# STM8S207C6 register map
Vendor: STMicroelectronics; Series: STM8S/STM8AF, medium density; File version: 1.0
CPU: other r1p0, big endian, no MPU, no FPU, 4 interrupt priority bits
Registers are 8-bit, read-write, reset 0x0 unless marked. A register's access mark holds for its fields unless they carry their own. Offsets are from the block's base; [hi:lo] are bit positions; {n}, {i} and the like mark numbered series.

## PORTI
Base 0x00005028
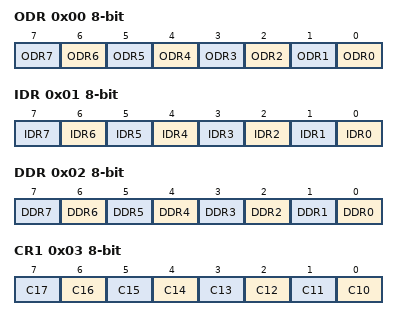
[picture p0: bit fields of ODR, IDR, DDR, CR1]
0x00 ODR — Port I data output latch register
  [n] ODR{n} (n=0..7)
0x01 IDR — Port I input pin value register
  [n] IDR{n} (n=0..7)
0x02 DDR — Port I data direction register
  [n] DDR{n} (n=0..7)
0x03 CR1 — Port I control register 1
  [n-10] C{n} (n=10..17)
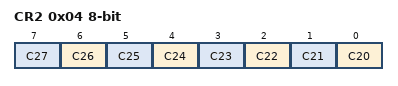
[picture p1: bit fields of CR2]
0x04 CR2 — Port I control register 2
  [n-20] C{n} (n=20..27)

## RST
Base 0x000050B3
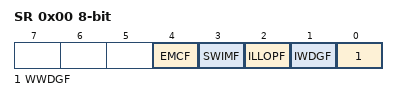
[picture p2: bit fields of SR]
0x00 SR — Reset status register
  [4] EMCF, [3] SWIMF, [2] ILLOPF, [1] IWDGF, [0] WWDGF

## SPI
Base 0x00005200
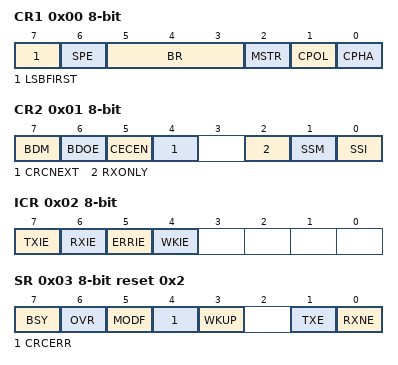
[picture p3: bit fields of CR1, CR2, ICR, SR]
0x00 CR1 — SPI control register 1
  [7] LSBFIRST, [6] SPE, [5:3] BR, [2] MSTR, [1] CPOL, [0] CPHA
0x01 CR2 — SPI control register 2
  [7] BDM, [6] BDOE, [5] CECEN, [4] CRCNEXT, [2] RXONLY, [1] SSM, [0] SSI
0x02 ICR — SPI interrupt control register
  [7] TXIE, [6] RXIE, [5] ERRIE, [4] WKIE
0x03 SR reset 0x2 — SPI status register
  [7] BSY, [6] OVR, [5] MODF, [4] CRCERR, [3] WKUP, [1] TXE, [0] RXNE
0x04 DR — SPI data register
0x05 CRCPR reset 0x7 — SPI CRC polynomial register
  [7:0] CRCPOLY
0x06 RXCRCR reset 0xFF — SPI Rx CRC register
  [7:0] RXCRC
0x07 TXCRCR reset 0xFF — SPI Tx CRC register
  [7:0] TXCRC

## SWIM
Base 0x00007F80
0x00 CSR — SWIM control status register

## TIM1
Base 0x00005250
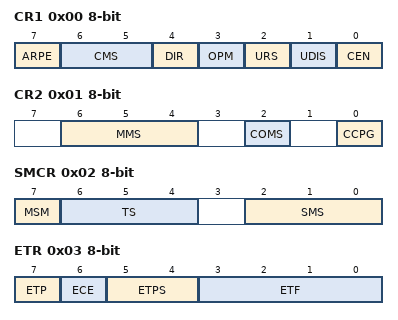
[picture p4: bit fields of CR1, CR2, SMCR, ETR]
0x00 CR1 — TIM1 control register 1
  [7] ARPE, [6:5] CMS, [4] DIR, [3] OPM, [2] URS, [1] UDIS, [0] CEN
0x01 CR2 — TIM1 control register 2
  [6:4] MMS, [2] COMS, [0] CCPG
0x02 SMCR — TIM1 slave mode control register
  [7] MSM, [6:4] TS, [2:0] SMS
0x03 ETR — TIM1 external trigger register
  [7] ETP, [6] ECE, [5:4] ETPS, [3:0] ETF
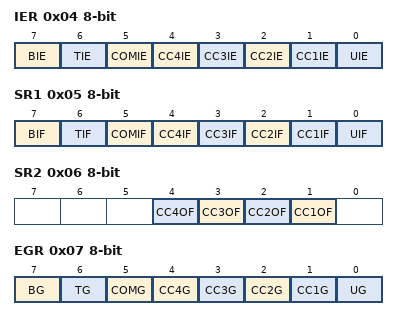
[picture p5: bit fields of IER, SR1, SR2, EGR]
0x04 IER — TIM1 Interrupt enable register
  [7] BIE, [6] TIE, [5] COMIE, [n] CC{n}IE (n=1..4), [0] UIE
0x05 SR1 — TIM1 status register 1
  [7] BIF, [6] TIF, [5] COMIF, [n] CC{n}IF (n=1..4), [0] UIF
0x06 SR2 — TIM1 status register 2
  [n] CC{n}OF (n=1..4)
0x07 EGR — TIM1 event generation register
  [7] BG, [6] TG, [5] COMG, [n] CC{n}G (n=1..4), [0] UG
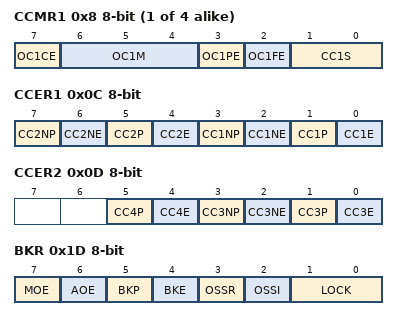
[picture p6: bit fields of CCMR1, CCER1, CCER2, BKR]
{0x7+i} CCMR{i} (i=1..4) — TIM1 capture/compare mode register {i}
  [7] OC{i}CE, [6:4] OC{i}M, [3] OC{i}PE, [2] OC{i}FE, [1:0] CC{i}S
0x0C CCER1 — TIM1 capture/compare enable register 1
  [7] CC2NP, [6] CC2NE, [5] CC2P, [4] CC2E, [3] CC1NP, [2] CC1NE, [1] CC1P, [0] CC1E
0x0D CCER2 — TIM1 capture/compare enable register 2
  [5] CC4P, [4] CC4E, [3] CC3NP, [2] CC3NE, [1] CC3P, [0] CC3E
0x0E CNTRH — TIM1 counter high
  [7:0] CNT
0x0F CNTRL — TIM1 counter low
  [7:0] CNT
0x10 PSCRH — TIM1 prescaler register high
  [7:0] PSC
0x11 PSCRL — TIM1 prescaler register low
  [7:0] PSC
0x12 ARRH reset 0xFF — TIM1 auto-reload register high
  [7:0] ARR
0x13 ARRL reset 0xFF — TIM1 auto-reload register low
  [7:0] ARR
0x14 RCR — TIM1 repetition counter register
  [7:0] REP
{0x13+2i} CCR{i}H (i=1..4) — TIM1 capture/compare register {i} high
  [7:0] CCR{i}
{0x14+2i} CCR{i}L (i=1..4) — TIM1 capture/compare register {i} low
  [7:0] CCR{i}
0x1D BKR — TIM1 break register
  [7] MOE, [6] AOE, [5] BKP, [4] BKE, [3] OSSR, [2] OSSI, [1:0] LOCK
0x1E DTR — TIM1 dead-time register
  [7:0] DTG
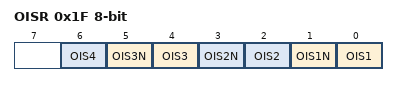
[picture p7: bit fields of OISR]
0x1F OISR — TIM1 output idle state register
  [2n-2] OIS{n} (n=1..4), [5] OIS3N, [3] OIS2N, [1] OIS1N

## TIM2
Base 0x00005300
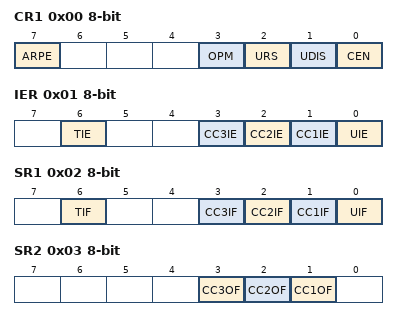
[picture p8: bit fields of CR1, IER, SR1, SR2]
0x00 CR1 — TIM2 control register 1
  [7] ARPE, [3] OPM, [2] URS, [1] UDIS, [0] CEN
0x01 IER — TIM2 interrupt enable register
  [6] TIE, [3] CC3IE, [2] CC2IE, [1] CC1IE, [0] UIE
0x02 SR1 — TIM2 status register 1
  [6] TIF, [3] CC3IF, [2] CC2IF, [1] CC1IF, [0] UIF
0x03 SR2 — TIM2 status register 2
  [3] CC3OF, [2] CC2OF, [1] CC1OF
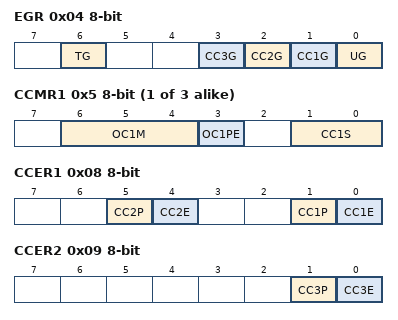
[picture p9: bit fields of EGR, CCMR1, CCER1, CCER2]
0x04 EGR — TIM2 event generation register
  [6] TG, [3] CC3G, [2] CC2G, [1] CC1G, [0] UG
{0x4+i} CCMR{i} (i=1..3) — TIM2 capture/compare mode register {i}
  [6:4] OC{i}M, [3] OC{i}PE, [1:0] CC{i}S
0x08 CCER1 — TIM2 capture/compare enable register 1
  [5] CC2P, [4] CC2E, [1] CC1P, [0] CC1E
0x09 CCER2 — TIM2 capture/compare enable register 2
  [1] CC3P, [0] CC3E
0x0A CNTRH — TIM2 counter high
  [7:0] CNT
0x0B CNTRL — TIM2 counter low
  [7:0] CNT
0x0C PSCR — TIM2 prescaler register
  [3:0] PSC
0x0D ARRH reset 0xFF — TIM2 auto-reload register high
  [7:0] ARR
0x0E ARRL reset 0xFF — TIM2 auto-reload register low
  [7:0] ARR
0x0F CCR1H — TIM2 capture/compare register 1 high
  [7:0] CCR1
{0xE+2i} CCR{i}L (i=1..3) — TIM2 capture/compare register {i} low
  [7:0] CCR{i}
0x11 CCR2H — TIM2 capture/compare reg
  [7:0] CCR2
0x13 CCR3H — TIM2 capture/compare register 3 high
  [7:0] CCR3

## TIM3
Base 0x00005320
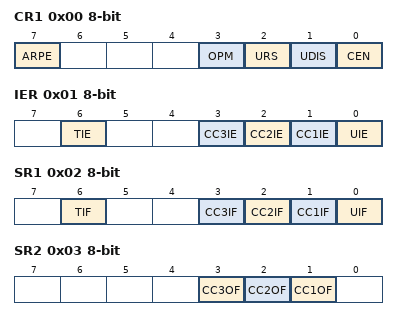
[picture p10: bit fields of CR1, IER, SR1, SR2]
0x00 CR1 — TIM3 control register 1
  [7] ARPE, [3] OPM, [2] URS, [1] UDIS, [0] CEN
0x01 IER — TIM3 interrupt enable register
  [6] TIE, [3] CC3IE, [2] CC2IE, [1] CC1IE, [0] UIE
0x02 SR1 — TIM3 status register 1
  [6] TIF, [3] CC3IF, [2] CC2IF, [1] CC1IF, [0] UIF
0x03 SR2 — TIM3 status register 2
  [3] CC3OF, [2] CC2OF, [1] CC1OF
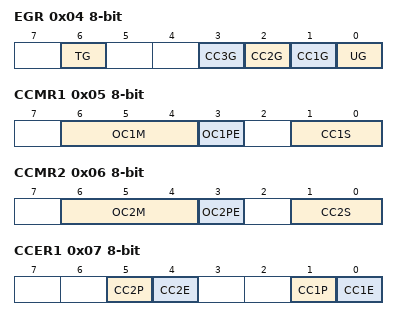
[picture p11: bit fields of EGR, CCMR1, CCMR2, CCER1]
0x04 EGR — TIM3 event generation register
  [6] TG, [3] CC3G, [2] CC2G, [1] CC1G, [0] UG
0x05 CCMR1 — TIM3 capture/compare mode register 1
  [6:4] OC1M, [3] OC1PE, [1:0] CC1S
0x06 CCMR2 — TIM3 capture/compare mode register 2
  [6:4] OC2M, [3] OC2PE, [1:0] CC2S
0x07 CCER1 — TIM3 capture/compare enable register 1
  [5] CC2P, [4] CC2E, [1] CC1P, [0] CC1E
0x08 CNTRH — TIM3 counter high
  [7:0] CNT
0x09 CNTRL — TIM3 counter low
  [7:0] CNT
0x0A PSCR — TIM3 prescaler register
  [3:0] PSC
0x0B ARRH reset 0xFF — TIM3 auto-reload register high
  [7:0] ARR
0x0C ARRL reset 0xFF — TIM3 auto-reload register low
  [7:0] ARR
0x0D CCR1H — TIM3 capture/compare register 1 high
  [7:0] CCR1
0x0E CCR1L — TIM3 capture/compare register 1 low
  [7:0] CCR1
0x0F CCR2H — TIM3 capture/compare register 2 high
  [7:0] CCR2
0x10 CCR2L — TIM3 capture/compare register 2 low
  [7:0] CCR2

## TIM4
Base 0x00005340
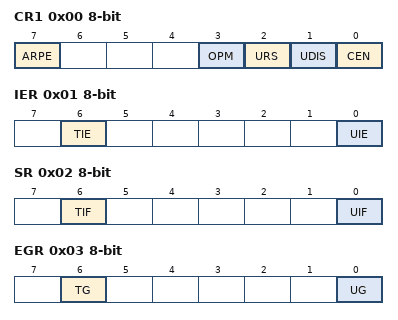
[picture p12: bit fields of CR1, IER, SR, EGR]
0x00 CR1 — TIM4 control register 1
  [7] ARPE, [3] OPM, [2] URS, [1] UDIS, [0] CEN
0x01 IER — TIM4 interrupt enable register
  [6] TIE, [0] UIE
0x02 SR — TIM4 status register
  [6] TIF, [0] UIF
0x03 EGR — TIM4 event generation register
  [6] TG, [0] UG
0x04 CNTR — TIM4 counter
  [7:0] CNT
0x05 PSCR — TIM4 prescaler register
  [2:0] PSC
0x06 ARR reset 0xFF — TIM4 auto-reload register

## UART1
Base 0x00005230
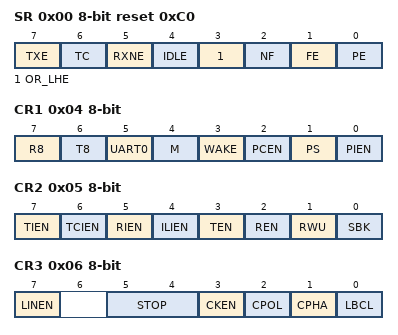
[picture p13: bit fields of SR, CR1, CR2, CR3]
0x00 SR reset 0xC0 — UART1 status register
  [7] TXE, [6] TC, [5] RXNE, [4] IDLE, [3] OR_LHE, [2] NF, [1] FE, [0] PE
0x01 DR — UART1 data register
0x02 BRR1 — UART1 baud rate register 1
  [7:0] UART_DIV
0x03 BRR2 — UART1 baud rate register 2
  [7:0] UART_DIV
0x04 CR1 — UART1 control register 1
  [7] R8, [6] T8, [5] UART0, [4] M, [3] WAKE, [2] PCEN, [1] PS, [0] PIEN
0x05 CR2 — UART1 control register 2
  [7] TIEN, [6] TCIEN, [5] RIEN, [4] ILIEN, [3] TEN, [2] REN, [1] RWU, [0] SBK
0x06 CR3 — UART1 control register 3
  [7] LINEN, [5:4] STOP, [3] CKEN, [2] CPOL, [1] CPHA, [0] LBCL
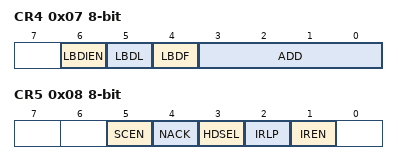
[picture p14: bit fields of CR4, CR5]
0x07 CR4 — UART1 control register 4
  [6] LBDIEN, [5] LBDL, [4] LBDF, [3:0] ADD
0x08 CR5 — UART1 control register 5
  [5] SCEN, [4] NACK, [3] HDSEL, [2] IRLP, [1] IREN
0x09 GTR — UART1 guard time register
  [7:0] GT
0x0A PSCR — UART1 prescaler register
  [7:0] PSC

## UART3
Base 0x00005240
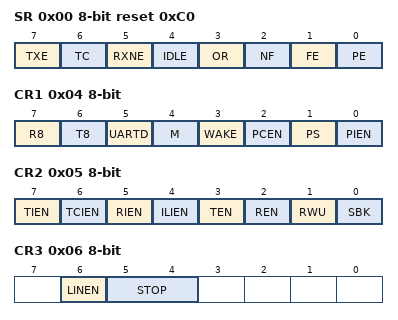
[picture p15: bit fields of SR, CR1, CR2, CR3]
0x00 SR reset 0xC0 — UART3 status register
  [7] TXE, [6] TC, [5] RXNE, [4] IDLE, [3] OR, [2] NF, [1] FE, [0] PE
0x01 DR — UART3 data register
0x02 BRR1 — UART3 baud rate register 1
  [7:0] UART_DIV
0x03 BRR2 — UART3 baud rate register 2
  [7:0] UART_DIV
0x04 CR1 — UART3 control register 1
  [7] R8, [6] T8, [5] UARTD, [4] M, [3] WAKE, [2] PCEN, [1] PS, [0] PIEN
0x05 CR2 — UART3 control register 2
  [7] TIEN, [6] TCIEN, [5] RIEN, [4] ILIEN, [3] TEN, [2] REN, [1] RWU, [0] SBK
0x06 CR3 — UART3 control register 3
  [6] LINEN, [5:4] STOP
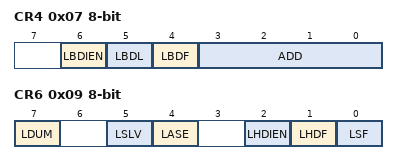
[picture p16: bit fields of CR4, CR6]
0x07 CR4 — UART3 control register 4
  [6] LBDIEN, [5] LBDL, [4] LBDF, [3:0] ADD
0x09 CR6 — UART3 control register 6
  [7] LDUM, [5] LSLV, [4] LASE, [2] LHDIEN, [1] LHDF, [0] LSF

## WWDG
Base 0x000050D1
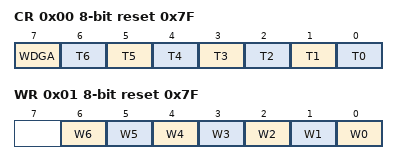
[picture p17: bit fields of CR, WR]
0x00 CR reset 0x7F — WWDG control register
  [7] WDGA, [n] T{n} (n=0..6)
0x01 WR reset 0x7F — WWDR window register
  [n] W{n} (n=0..6)
